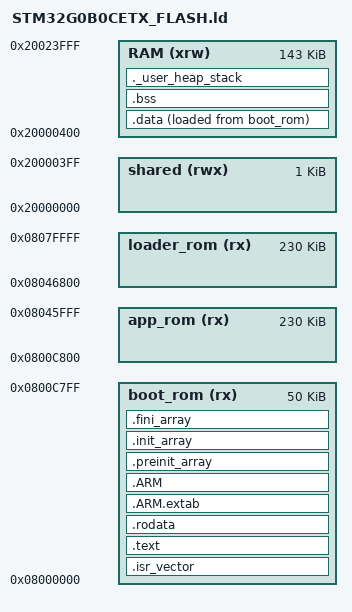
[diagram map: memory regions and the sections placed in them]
/*
******************************************************************************
**
** @file        : LinkerScript.ld
**
** @author      : Auto-generated by STM32CubeIDE
**
** @brief       : Linker script for STM32G0B0CETx Device from STM32G0 series
**                      512Kbytes FLASH
**                      144Kbytes RAM
**
**                Set heap size, stack size and stack location according
**                to application requirements.
**
**                Set memory bank area and size if external memory is used
**
**  Target      : STMicroelectronics STM32
**
**  Distribution: The file is distributed as is, without any warranty
**                of any kind.
**
******************************************************************************
** @attention
**
** Copyright (c) 2023 STMicroelectronics.
** All rights reserved.
**
** This software is licensed under terms that can be found in the LICENSE file
** in the root directory of this software component.
** If no LICENSE file comes with this software, it is provided AS-IS.
**
******************************************************************************
*/

/* Entry Point */
ENTRY(Reset_Handler)

/* Highest address of the user mode stack */
_estack = ORIGIN(RAM) + LENGTH(RAM); /* end of "RAM" Ram type memory */

_Min_Heap_Size = 0x200; /* required amount of heap */
_Min_Stack_Size = 0x400; /* required amount of stack */

/* Memories definition */
MEMORY
{
  RAM    (xrw)    : ORIGIN = 0x20000400,   LENGTH = 143K
  shared (rwx)  : ORIGIN = 0x20000000, LENGTH = 1K /* Shared RAM 1024 bytes */
  
   
  boot_rom (rx)  : ORIGIN = 0x08000000, LENGTH = 50K /* flash Partition boot, 40k  */
  app_rom (rx)  : ORIGIN = 0x0800C800, LENGTH = 230K /* flash Partition loader, 40k */
  loader_rom (rx)  : ORIGIN = 0x08046800, LENGTH = 230K /* flash Partition app, 40k */
  
}

/* VARIABLES */
__boot_rom_start__ = ORIGIN(boot_rom);
__boot_rom_size__ = LENGTH(boot_rom);

/* Only App Rom is for runing the main application */
__app_rom_start__ = ORIGIN(app_rom);
__app_rom_size__ = LENGTH(app_rom);

/* Only Loader Rom is for runing the main application */
__loader_rom_start__ = ORIGIN(loader_rom);
__loader_rom_size__ = LENGTH(loader_rom);

__shared_data_start__ = ORIGIN(shared);
/* Sections */
SECTIONS
{
  /* The startup code into "FLASH" Rom type memory */
  .isr_vector :
  {
    . = ALIGN(4);
    KEEP(*(.isr_vector)) /* Startup code */
    . = ALIGN(4);
  } >boot_rom

  /* The program code and other data into "FLASH" Rom type memory */
  .text :
  {
    . = ALIGN(4);
    *(.text)           /* .text sections (code) */
    *(.text*)          /* .text* sections (code) */
    *(.glue_7)         /* glue arm to thumb code */
    *(.glue_7t)        /* glue thumb to arm code */
    *(.eh_frame)

    KEEP (*(.init))
    KEEP (*(.fini))

    . = ALIGN(4);
    _etext = .;        /* define a global symbols at end of code */
  } >boot_rom

  /* Constant data into "FLASH" Rom type memory */
  .rodata :
  {
    . = ALIGN(4);
    *(.rodata)         /* .rodata sections (constants, strings, etc.) */
    *(.rodata*)        /* .rodata* sections (constants, strings, etc.) */
    . = ALIGN(4);
  } >boot_rom

  .ARM.extab   : {
    . = ALIGN(4);
    *(.ARM.extab* .gnu.linkonce.armextab.*)
    . = ALIGN(4);
  } >boot_rom

  .ARM : {
    . = ALIGN(4);
    __exidx_start = .;
    *(.ARM.exidx*)
    __exidx_end = .;
    . = ALIGN(4);
  } >boot_rom

  .preinit_array     :
  {
    . = ALIGN(4);
    PROVIDE_HIDDEN (__preinit_array_start = .);
    KEEP (*(.preinit_array*))
    PROVIDE_HIDDEN (__preinit_array_end = .);
    . = ALIGN(4);
  } >boot_rom

  .init_array :
  {
    . = ALIGN(4);
    PROVIDE_HIDDEN (__init_array_start = .);
    KEEP (*(SORT(.init_array.*)))
    KEEP (*(.init_array*))
    PROVIDE_HIDDEN (__init_array_end = .);
    . = ALIGN(4);
  } >boot_rom

  .fini_array :
  {
    . = ALIGN(4);
    PROVIDE_HIDDEN (__fini_array_start = .);
    KEEP (*(SORT(.fini_array.*)))
    KEEP (*(.fini_array*))
    PROVIDE_HIDDEN (__fini_array_end = .);
    . = ALIGN(4);
  } >boot_rom

  /* Used by the startup to initialize data */
  _sidata = LOADADDR(.data);

  /* Initialized data sections into "RAM" Ram type memory */
  .data :
  {
    . = ALIGN(4);
    _sdata = .;        /* create a global symbol at data start */
    *(.data)           /* .data sections */
    *(.data*)          /* .data* sections */
    *(.RamFunc)        /* .RamFunc sections */
    *(.RamFunc*)       /* .RamFunc* sections */

    . = ALIGN(4);
    _edata = .;        /* define a global symbol at data end */

  } >RAM AT> boot_rom

  /* Uninitialized data section into "RAM" Ram type memory */
  . = ALIGN(4);
  .bss :
  {
    /* This is used by the startup in order to initialize the .bss section */
    _sbss = .;         /* define a global symbol at bss start */
    __bss_start__ = _sbss;
    *(.bss)
    *(.bss*)
    *(COMMON)

    . = ALIGN(4);
    _ebss = .;         /* define a global symbol at bss end */
    __bss_end__ = _ebss;
  } >RAM

  /* User_heap_stack section, used to check that there is enough "RAM" Ram  type memory left */
  ._user_heap_stack :
  {
    . = ALIGN(8);
    PROVIDE ( end = . );
    PROVIDE ( _end = . );
    . = . + _Min_Heap_Size;
    . = . + _Min_Stack_Size;
    . = ALIGN(8);
  } >RAM

  /* Remove information from the compiler libraries */
  /DISCARD/ :
  {
    libc.a ( * )
    libm.a ( * )
    libgcc.a ( * )
  }

  .ARM.attributes 0 : { *(.ARM.attributes) }
}

__isr_vector_start__ = LOADADDR(.isr_vector);
